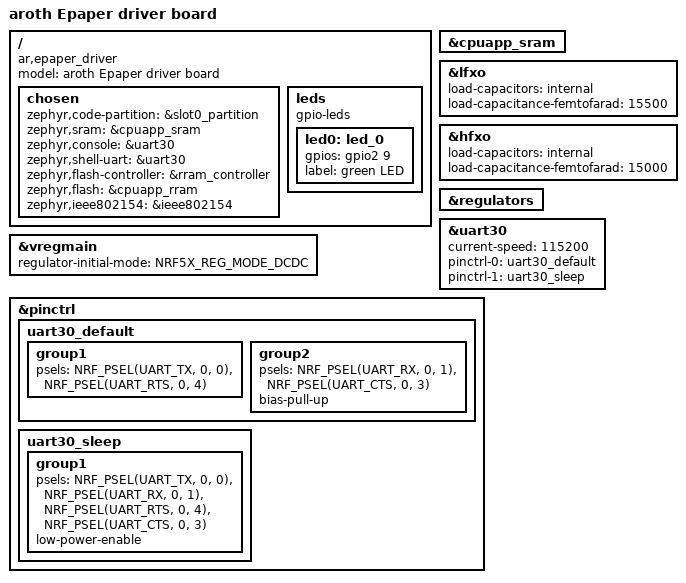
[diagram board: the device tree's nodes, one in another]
/dts-v1/;

#include <nordic/nrf54l15_cpuapp.dtsi>

/ {
        compatible = "ar,epaper_driver";
        model = "aroth Epaper driver board";

        chosen {
          zephyr,code-partition = &slot0_partition;
          zephyr,sram = &cpuapp_sram;
          zephyr,console = &uart30;
          zephyr,shell-uart = &uart30;
          zephyr,flash-controller = &rram_controller;
          zephyr,flash = &cpuapp_rram;
          zephyr,ieee802154 = &ieee802154;
        };

        leds {
            compatible = "gpio-leds";
            led0: led_0 {
              gpios = <&gpio2 9 GPIO_ACTIVE_HIGH>;
              label = "green LED";
          };
        };
};

&cpuapp_sram {
        status = "okay";
};

&lfxo {
        load-capacitors = "internal";
        load-capacitance-femtofarad = <15500>;
};

&hfxo {
        load-capacitors = "internal";
        load-capacitance-femtofarad = <15000>;
};

&regulators {
        status = "okay";
};

&vregmain {
        status = "okay";
        regulator-initial-mode = <NRF5X_REG_MODE_DCDC>;
};


&uart30 {
        current-speed = <115200>;
        pinctrl-0 = <&uart30_default>;
        pinctrl-1 = <&uart30_sleep>;
        pinctrl-names = "default", "sleep";
};

&pinctrl {
         /omit-if-no-ref/ uart30_default: uart30_default {
                group1 {
                        psels = <NRF_PSEL(UART_TX, 0, 0)>,
                                <NRF_PSEL(UART_RTS, 0, 4)>;
                };

                group2 {
                        psels = <NRF_PSEL(UART_RX, 0, 1)>,
                                <NRF_PSEL(UART_CTS, 0, 3)>;
                        bias-pull-up;
                };
        };

        /omit-if-no-ref/ uart30_sleep: uart30_sleep {
                group1 {
                        psels = <NRF_PSEL(UART_TX, 0, 0)>,
                                <NRF_PSEL(UART_RX, 0, 1)>,
                                <NRF_PSEL(UART_RTS, 0, 4)>,
                                <NRF_PSEL(UART_CTS, 0, 3)>;
                        low-power-enable;
                };
        };
};


/* Include default memory partition configuration file */
#include <nordic/nrf54l15_partition.dtsi>
